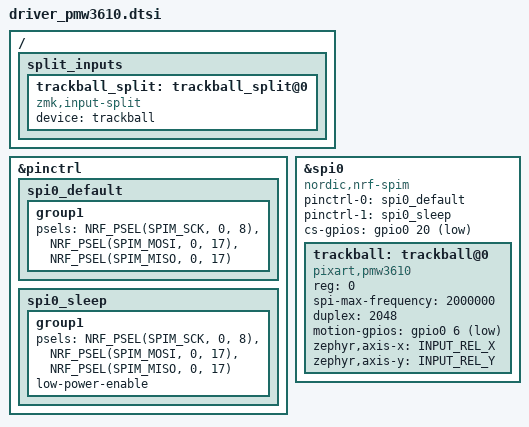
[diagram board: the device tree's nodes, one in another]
/* Gemini 3 Pro - The Final Link Fix */
/* 하드웨어: SCK(8), MOSI(17), CS(20), IRQ(6) - 판매자 원본 */
/* 통신: 3-wire Duplex */
/* 소프트웨어: Badjeff Driver + Split Input 연결 */

#include <dt-bindings/input/input-event-codes.h>

&pinctrl {
    spi0_default: spi0_default {
        group1 {
            /* 3-wire SPI: MOSI와 MISO를 17번으로 통일 */
            psels = <NRF_PSEL(SPIM_SCK, 0, 8)>,
                <NRF_PSEL(SPIM_MOSI, 0, 17)>,
                <NRF_PSEL(SPIM_MISO, 0, 17)>;
        };
    };

    spi0_sleep: spi0_sleep {
        group1 {
            psels = <NRF_PSEL(SPIM_SCK, 0, 8)>,
                <NRF_PSEL(SPIM_MOSI, 0, 17)>,
                <NRF_PSEL(SPIM_MISO, 0, 17)>;
            low-power-enable;
        };
    };
};

&spi0 {
    status = "okay";
    compatible = "nordic,nrf-spim";
    pinctrl-0 = <&spi0_default>;
    pinctrl-1 = <&spi0_sleep>;
    pinctrl-names = "default", "sleep";
    
    /* CS 핀 */
    cs-gpios = <&gpio0 20 GPIO_ACTIVE_LOW>;

    trackball: trackball@0 {
        status = "okay";
        compatible = "pixart,pmw3610";
        reg = <0>;
        spi-max-frequency = <2000000>;
        
        /* [핵심] 3-wire 모드 */
        duplex = <2048>;

        /* [핵심] 핀 이름: motion-gpios (최신 badjeff 호환) */
        motion-gpios = <&gpio0 6 (GPIO_ACTIVE_LOW | GPIO_PULL_UP)>;
        
        /* [핵심] 축 설정 (필수) */
        zephyr,axis-x = <INPUT_REL_X>;
        zephyr,axis-y = <INPUT_REL_Y>;

        /* 주의: 여기서 리스너나 스크롤 설정을 하지 않습니다. */
        /* 형님의 .keymap 파일에서 이미 다 하고 있기 때문입니다. */
    };
};

/* [여기가 오늘 수정한 가장 중요한 부분] */
/* 우리가 만든 하드웨어(&trackball)를 시스템의 중계기(trackball_split)에 연결합니다 */
/ {
    split_inputs {
        trackball_split: trackball_split@0 {
            compatible = "zmk,input-split";
            device = <&trackball>; /* 끊어진 연결고리를 잇는 코드 */
        };
    };
};
